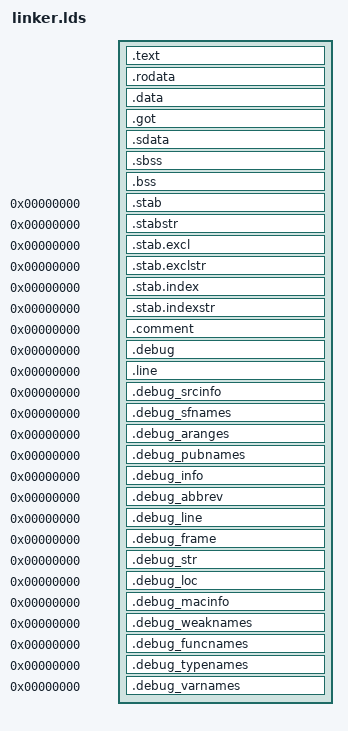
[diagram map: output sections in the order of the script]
/*******************************************************************************
* Filename:    src/arch-alpha/linker.lds                                       *
* Description: Elf-loader - ELF file kernel/application bootstraper, Alpha     *
*              architecture specific linnker script to link the elf-loader     *
*              binary with the dite image it is to load embedded in it.        *
* Authors:     Adam 'WeirdArms' Wiggins <awiggins@cse.unsw.edu.au>.            *
* Created:     2004-12-01                                                      *
********************************************************************************
*                                                                              *
* Australian Public Licence B (OZPLB)                                          *
*                                                                              *
* Version 1-0                                                                  *
*                                                                              *
* Copyright (c) 2004 - 2005 University of New South Wales, Australia           *
*                                                                              *
* All rights reserved.                                                         *
*                                                                              *
* Developed by: Operating Systems, Embedded and                                *
*               Distributed Systems Group (DiSy)                               *
*               University of New South Wales                                  *
*               http://www.disy.cse.unsw.edu.au                                *
*                                                                              *
* Permission is granted by University of New South Wales, free of charge, to   *
* any person obtaining a copy of this software and any associated              *
* documentation files (the "Software") to deal with the Software without       *
* restriction, including (without limitation) the rights to use, copy,         *
* modify, adapt, merge, publish, distribute, communicate to the public,        *
* sublicense, and/or sell, lend or rent out copies of the Software, and        *
* to permit persons to whom the Software is furnished to do so, subject        *
* to the following conditions:                                                 *
*                                                                              *
*     * Redistributions of source code must retain the above copyright         *
*       notice, this list of conditions and the following disclaimers.         *
*                                                                              *
*     * Redistributions in binary form must reproduce the above                *
*       copyright notice, this list of conditions and the following            *
*       disclaimers in the documentation and/or other materials provided       *
*       with the distribution.                                                 *
*                                                                              *
*     * Neither the name of University of New South Wales, nor the names of    *
*        its contributors, may be used to endorse or promote products derived  *
*       from this Software without specific prior written permission.          *
*                                                                              *
* EXCEPT AS EXPRESSLY STATED IN THIS LICENCE AND TO THE FULL EXTENT            *
* PERMITTED BY APPLICABLE LAW, THE SOFTWARE IS PROVIDED "AS-IS", AND           *
* NATIONAL ICT AUSTRALIA AND ITS CONTRIBUTORS MAKE NO REPRESENTATIONS,         *
* WARRANTIES OR CONDITIONS OF ANY KIND, EXPRESS OR IMPLIED, INCLUDING          *
* BUT NOT LIMITED TO ANY REPRESENTATIONS, WARRANTIES OR CONDITIONS             *
* REGARDING THE CONTENTS OR ACCURACY OF THE SOFTWARE, OR OF TITLE,             *
* MERCHANTABILITY, FITNESS FOR A PARTICULAR PURPOSE, NONINFRINGEMENT,          *
* THE ABSENCE OF LATENT OR OTHER DEFECTS, OR THE PRESENCE OR ABSENCE OF        *
* ERRORS, WHETHER OR NOT DISCOVERABLE.                                         *
*                                                                              *
* TO THE FULL EXTENT PERMITTED BY APPLICABLE LAW, IN NO EVENT SHALL            *
* NATIONAL ICT AUSTRALIA OR ITS CONTRIBUTORS BE LIABLE ON ANY LEGAL            *
* THEORY (INCLUDING, WITHOUT LIMITATION, IN AN ACTION OF CONTRACT,             *
* NEGLIGENCE OR OTHERWISE) FOR ANY CLAIM, LOSS, DAMAGES OR OTHER               *
* LIABILITY, INCLUDING (WITHOUT LIMITATION) LOSS OF PRODUCTION OR              *
* OPERATION TIME, LOSS, DAMAGE OR CORRUPTION OF DATA OR RECORDS; OR LOSS       *
* OF ANTICIPATED SAVINGS, OPPORTUNITY, REVENUE, PROFIT OR GOODWILL, OR         *
* OTHER ECONOMIC LOSS; OR ANY SPECIAL, INCIDENTAL, INDIRECT,                   *
* CONSEQUENTIAL, PUNITIVE OR EXEMPLARY DAMAGES, ARISING OUT OF OR IN           *
* CONNECTION WITH THIS LICENCE, THE SOFTWARE OR THE USE OF OR OTHER            *
* DEALINGS WITH THE SOFTWARE, EVEN IF NATIONAL ICT AUSTRALIA OR ITS            *
* CONTRIBUTORS HAVE BEEN ADVISED OF THE POSSIBILITY OF SUCH CLAIM, LOSS,       *
* DAMAGES OR OTHER LIABILITY.                                                  *
*                                                                              *
* If applicable legislation implies representations, warranties, or            *
* conditions, or imposes obligations or liability on University of New South   *
* Wales or one of its contributors in respect of the Software that             *
* cannot be wholly or partly excluded, restricted or modified, the             *
* liability of University of New South Wales or the contributor is limited, to *
* the full extent permitted by the applicable legislation, at its              *
* option, to:                                                                  *
* a.  in the case of goods, any one or more of the following:                  *
* i.  the replacement of the goods or the supply of equivalent goods;          *
* ii.  the repair of the goods;                                                *
* iii. the payment of the cost of replacing the goods or of acquiring          *
*  equivalent goods;                                                           *
* iv.  the payment of the cost of having the goods repaired; or                *
* b.  in the case of services:                                                 *
* i.  the supplying of the services again; or                                  *
* ii.  the payment of the cost of having the services supplied again.          *
*                                                                              *
* The construction, validity and performance of this licence is governed       *
* by the laws in force in New South Wales, Australia.                          *
*                                                                              *
*******************************************************************************/

OUTPUT_FORMAT("elf64-alpha")
OUTPUT_ARCH(alpha)
ENTRY(_start)

SECTIONS
{
	_text = .;
	  .text : { 
        *(.text.start)
        *(.text) 
	}
	_etext = .;

	/* Global data */
	_data = .;
	.rodata : { 
	*(.rodata) 
	*(.rodata.*) 
	. = ALIGN(16);
        mod_dite_start = .;
        *(.mod_kernel)
        mod_dite_end = .;
	}
	.data : { *(.data) *(.gnu.linkonce.d*) CONSTRUCTORS }
	__gp = ALIGN (8) + 0x200000;
	.got : { *(.got.plt) *(.got) }
	/* We want the small data sections together, so single-instruction
	   offsets can access them all, and initialized data all before
	   uninitialized, so we can shorten the on-disk segment size.  */
	.sdata : { *(.sdata) }
	_edata  =  .;
	_bss = .;
	.sbss : { *(.sbss) *(.scommon) }
  	.bss : { *(.bss) *(COMMON) }
  	. = ALIGN(64 / 8);
  	_end = . ;

	/* Stabs debugging sections.  */
	.stab 0 : { *(.stab) }
	.stabstr 0 : { *(.stabstr) }
	.stab.excl 0 : { *(.stab.excl) }
	.stab.exclstr 0 : { *(.stab.exclstr) }
	.stab.index 0 : { *(.stab.index) }
	.stab.indexstr 0 : { *(.stab.indexstr) }
	.comment 0 : { *(.comment) }
	/* DWARF debug sections.
	   Symbols in the DWARF debugging sections are relative to the
	   beginning of the section so we begin them at 0.  */
	/* DWARF 1 */
	.debug          0 : { *(.debug) }
	.line           0 : { *(.line) }
	/* GNU DWARF 1 extensions */
	.debug_srcinfo  0 : { *(.debug_srcinfo) }
	.debug_sfnames  0 : { *(.debug_sfnames) }
	/* DWARF 1.1 and DWARF 2 */
	.debug_aranges  0 : { *(.debug_aranges) }
	.debug_pubnames 0 : { *(.debug_pubnames) }
	/* DWARF 2 */
	.debug_info     0 : { *(.debug_info) }
	.debug_abbrev   0 : { *(.debug_abbrev) }
	.debug_line     0 : { *(.debug_line) }
	.debug_frame    0 : { *(.debug_frame) }
	.debug_str      0 : { *(.debug_str) }
	.debug_loc      0 : { *(.debug_loc) }
	.debug_macinfo  0 : { *(.debug_macinfo) }
	/* SGI/MIPS DWARF 2 extensions */
	.debug_weaknames 0 : { *(.debug_weaknames) }
	.debug_funcnames 0 : { *(.debug_funcnames) }
	.debug_typenames 0 : { *(.debug_typenames) }
	.debug_varnames  0 : { *(.debug_varnames) }
	/* These must appear regardless of  .  */
}
